# APM32F103x6 register map
File version: 1.0
APM32F103x6 SVD APM32F103x6 ARM 32-bit Cortex-M3 Microcontroller based device
CPU: CM3 r2p1, little endian, no MPU, no FPU, 4 interrupt priority bits
Registers are 32-bit, read-write, reset 0x0 unless marked. A register's access mark holds for its fields unless they carry their own. Offsets are from the block's base; lines under a group give offsets from that group; [hi:lo] are bit positions; {n}, {i} and the like mark numbered series; 'fields as' and 'values as' point back to an identical list; <NAME> marks a mode.

## Memory map
0x40000000 TMR2 size 0x400 — General purpose timer
0x40000400 TMR3 size 0x400 — General purpose timer
0x40002800 RTC size 0x400 — Real time clock
0x40002C00 WWDT size 0x400 — Window watchdog
0x40003000 IWDT size 0x400 — Independent watchdog
0x40004400 USART2 size 0x400
0x40005400 I2C1 size 0x400 — Inter integrated circuit 1
0x40005C00 USBD size 0x400 — Universal serial bus full-speed device interface
0x40006400 CAN1 size 0x400 — Controller area network
0x40006C00 BAKPR size 0x400 — Bakr registers
0x40007000 PMU size 0x400 — Power control
0x40010000 AFIO size 0x400 — Alternate function I/O
0x40010400 EINT size 0x400 — External Interrupt
0x40010800 GPIOA size 0x400 — General purpose I/O
0x40010C00 GPIOB size 0x400
0x40011000 GPIOC size 0x400
0x40011400 GPIOD size 0x400
0x40012400 ADC1 size 0x400 — Analog to digital converter
0x40012800 ADC2 size 0x400 — Analog to digital converter
0x40012C00 TMR1 size 0x400 — Advanced timer
0x40013000 SPI1 size 0x400 — Serial peripheral interface
0x40013800 USART1 size 0x400 — Universal synchronous asynchronous receiver transmitter
0x40020000 DMA1 size 0x400 — DMA1 controller
0x40021000 RCM size 0x400 — Reset and clock management unit
0x40022000 FMC size 0x400 — Flash memory controller
0x40023000 CRC size 0x400 — CRC calculation unit
0xE000E000 NVIC size 0x1001 — Nested Vectored Interrupt Controller
0xE0042000 DBGMCU size 0x400 — Debug support

## Interrupts
0 WWDT — Window Watchdog interrupt
1 PVD (PMU) — PVD through EINT line detection interrupt
2 TAMPER (EINT) — Tamper interrupt
3 RTC — RTC global interrupt
4 FLASH (FMC) — Flash global interrupt
5 RCM — RCM global interrupt
6 EINT0 (EINT) — EINT Line0 interrupt
7 EINT1 (EINT) — EINT Line1 interrupt
8 EINT2 (EINT) — EINT Line2 interrupt
9 EINT3 (EINT) — EINT Line3 interrupt
10 EINT4 (EINT) — EINT Line4 interrupt
11 DMA1_Channel1 (DMA1) — DMA1 Channel1 global interrupt
12 DMA1_Channel2 (DMA1) — DMA1 Channel2 global interrupt
13 DMA1_Channel3 (DMA1) — DMA1 Channel3 global interrupt
14 DMA1_Channel4 (DMA1) — DMA1 Channel4 global interrupt
15 DMA1_Channel5 (DMA1) — DMA1 Channel5 global interrupt
16 DMA1_Channel6 (DMA1) — DMA1 Channel6 global interrupt
17 DMA1_Channel7 (DMA1) — DMA1 Channel7 global interrupt
18 ADC1_2 (ADC1, ADC2) — ADC1 global interrupt
19 USBD1_HP_CAN1_TX (CAN1) — USB Device 1 HP and CAN1 TX interrupts
20 USBD1_LP_CAN1_RX0 (CAN1) — USB Device 1 LP and CAN1 RX0 interrupts
21 CAN1_RX1 (CAN1) — CAN1 RX1 interrupt
22 CAN1_SCE (CAN1) — CAN1 SCE interrupt
23 EINT9_5 (EINT) — EINT Line[9:5] interrupts
24 TMR1_BRK (TMR1) — TMR1 Break interrupt
25 TMR1_UP (TMR1) — TMR1 Update interrupt
26 TMR1_TRG_COM (TMR1) — TMR1 Trigger
27 TMR1_CC (TMR1) — TMR1 Capture Compare interrupt
28 TMR2 — TMR2 global interrupt
29 TMR3 — TMR3 global interrupt
31 I2C1_EV (I2C1) — I2C1 event interrupt
32 I2C1_ER (I2C1) — I2C1 error interrupt
35 SPI1 — SPI1 global interrupt
37 USART1 — USART1 global interrupt
38 USART2 — USART2 global interrupt
40 EINT15_10 (EINT) — EINT Line[15:10] interrupts
41 RTCAlarm (RTC) — RTC Alarms through EXTI line interrupt
42 USBDWakeUp (USBD) — USB Device FS Wakeup through EINT line interrupt

## CRC — CRC calculation unit
Base 0x40023000
0x00 DATA reset 0xFFFFFFFF
0x04 INDATA — Independent Data register
  [7:0] INDATA
0x08 CTRL wo — Control register
  [0] RST — Reset bit

## FMC — Flash memory controller
Base 0x40022000
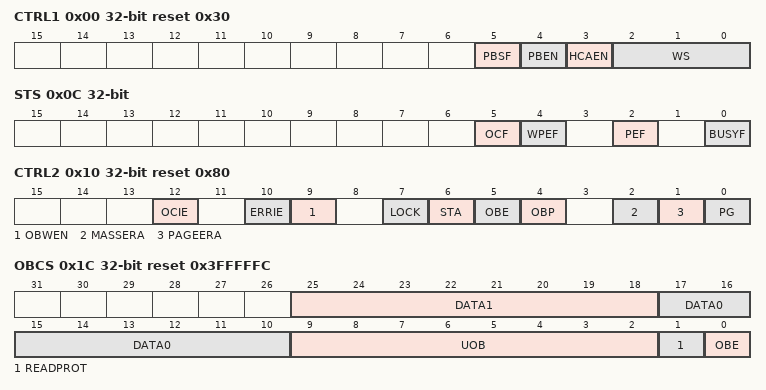
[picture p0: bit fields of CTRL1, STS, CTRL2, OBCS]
0x00 CTRL1 access per field reset 0x30 — Flash access control register
  [5] PBSF ro — Prefetch buffer status
  [4] PBEN rw — Prefetch buffer enable
  [3] HCAEN rw — Flash half cycle access enable
  [2:0] WS rw — Latency
0x04 KEY wo
  [31:0] KEY — FMC key
0x08 OBKEY wo — option byte key register
  [31:0] OBKEY — Option byte key
0x0C STS access per field — status register
  [5] OCF rw — End of operation
  [4] WPEF rw — Write protection error
  [2] PEF rw — Programming error
  [0] BUSYF ro — Busy
0x10 CTRL2 reset 0x80 — Control register
  [12] OCIE — End of operation interrupt enable
  [10] ERRIE — Error interrupt enable
  [9] OBWEN — Option bytes write enable
  [7] LOCK
  [6] STA — Start
  [5] OBE — Option byte erase
  [4] OBP — Option byte programming
  [2] MASSERA — Mass Erase
  [1] PAGEERA — Page Erase
  [0] PG — Programming
0x14 ADDR wo — Flash address register
  [31:0] ADDR — Flash Address
0x1C OBCS ro reset 0x3FFFFFC — Option byte register
  [25:18] DATA1
  [17:10] DATA0 — Data1
  [9:2] UOB
  [1] READPROT — Read protection
  [0] OBE — Option byte error
0x20 WRTPROT ro reset 0xFFFFFFFF — Write protection register
  [31:0] WRTPROT — Write protect
